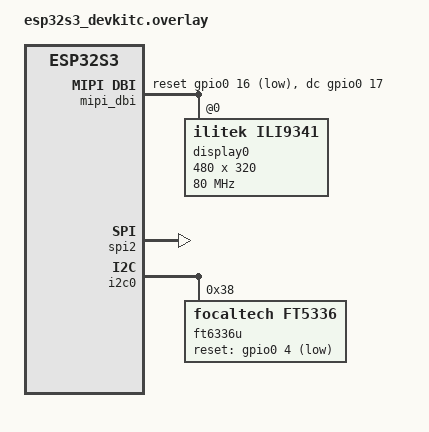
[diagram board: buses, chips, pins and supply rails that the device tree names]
/* Auto-generated by @typecad/framework-zephyr from cuttlefish.config.ts. */
/* Enables peripherals the program uses. West merges this over the board DT. */

&dma {
    status = "okay";
};

&spi2 {
    status = "okay";
    cs-gpios = <&gpio0 5 GPIO_ACTIVE_LOW>;
    dma-enabled;
    dmas = <&dma 0>, <&dma 1>;
    dma-names = "rx", "tx";
};

/ {
    mipi_dbi: mipi-dbi {
        compatible = "zephyr,mipi-dbi-spi";
        spi-dev = <&spi2>;
        dc-gpios = <&gpio0 17 GPIO_ACTIVE_HIGH>;
        reset-gpios = <&gpio0 16 GPIO_ACTIVE_LOW>;
        write-only;
        #address-cells = <1>;
        #size-cells = <0>;
        display0: display@0 {
            compatible = "ilitek,ili9341";
            reg = <0>;
            mipi-max-frequency = <80000000>;
            mipi-mode = "MIPI_DBI_MODE_SPI_4WIRE";
            pixel-format = <0>;
            width = <480>;
            height = <320>;
            rotation = <90>;
        };
    };
};

&pinctrl {
    i2c0_touch: i2c0_touch {
        group1 {
            pinmux = <I2C0_SDA_GPIO8>, <I2C0_SCL_GPIO9>;
            bias-pull-up;
            drive-open-drain;
        };
    };
};

&i2c0 {
    status = "okay";
    pinctrl-0 = <&i2c0_touch>;
    pinctrl-names = "default";
    ft6336u: ft6336u@38 {
        compatible = "focaltech,ft5336";
        reg = <0x38>;
        reset-gpios = <&gpio0 4 GPIO_ACTIVE_LOW>;
    };
};

&psram0 {
    status = "okay";
    size = <(DT_SIZE_M(8))>;
};
